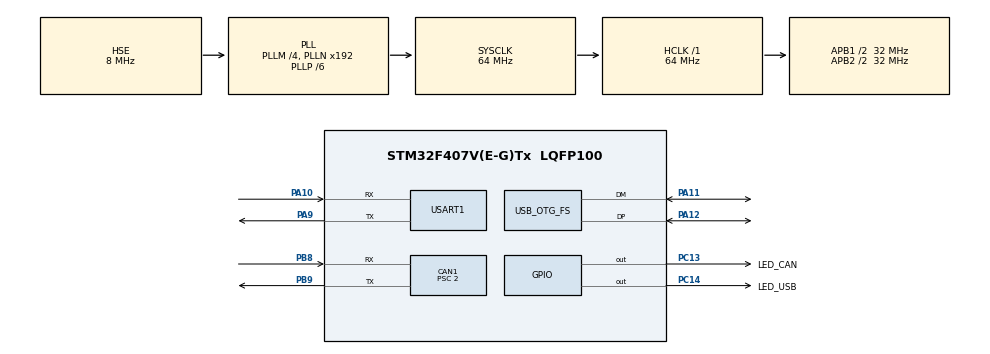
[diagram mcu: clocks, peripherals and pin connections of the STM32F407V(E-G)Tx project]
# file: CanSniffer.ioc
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CAN1.ABOM=ENABLE
CAN1.BS1=CAN_BS1_13TQ
CAN1.BS2=CAN_BS2_2TQ
CAN1.CalculateBaudRate=1000000
CAN1.CalculateTimeBit=1000
CAN1.CalculateTimeQuantum=62.5
CAN1.NART=ENABLE
CAN1.Prescaler=2
CAN1.RFLM=ENABLE
CAN1.TXFP=ENABLE
Mcu.Family=STM32F4
Mcu.Name=STM32F407V(E-G)Tx
Mcu.Package=LQFP100
NVIC.CAN1_RX0_IRQn=true\:0\:0\:true\:false\:true\:true\:true\:true
NVIC.CAN1_RX1_IRQn=true\:1\:0\:true\:false\:true\:true\:true\:true
NVIC.CAN1_SCE_IRQn=true\:1\:0\:true\:false\:true\:true\:true\:true
NVIC.CAN1_TX_IRQn=true\:1\:0\:true\:false\:true\:true\:true\:true
NVIC.OTG_FS_IRQn=true\:0\:0\:false\:false\:true\:false\:true\:true
NVIC.PriorityGroup=NVIC_PRIORITYGROUP_4
NVIC.TIM8_TRG_COM_TIM14_IRQn=true\:1\:0\:true\:false\:true\:true\:true\:true
NVIC.USART1_IRQn=true\:1\:0\:true\:false\:true\:true\:true\:true
PA10.Mode=Asynchronous
PA10.Signal=USART1_RX
PA11.Mode=Device_Only
PA11.Signal=USB_OTG_FS_DM
PA12.Mode=Device_Only
PA12.Signal=USB_OTG_FS_DP
PA13.Mode=Serial_Wire
PA13.Signal=SYS_JTMS-SWDIO
PA14.Mode=Serial_Wire
PA14.Signal=SYS_JTCK-SWCLK
PA9.Mode=Asynchronous
PA9.Signal=USART1_TX
PB8.GPIO_PuPd=GPIO_PULLUP
PB8.Mode=CAN_Activate
PB8.Signal=CAN1_RX
PB9.GPIO_PuPd=GPIO_PULLUP
PB9.Mode=CAN_Activate
PB9.Signal=CAN1_TX
PC13-ANTI_TAMP.GPIO_Label=LED_CAN
PC13-ANTI_TAMP.Signal=GPIO_Output
PC14-OSC32_IN.GPIO_Label=LED_USB
PC14-OSC32_IN.Signal=GPIO_Output
PH0-OSC_IN.Mode=HSE-External-Oscillator
PH0-OSC_IN.Signal=RCC_OSC_IN
PH1-OSC_OUT.Mode=HSE-External-Oscillator
PH1-OSC_OUT.Signal=RCC_OSC_OUT
ProjectManager.HeapSize=0x200
ProjectManager.StackSize=0x400
ProjectManager.TargetToolchain=STM32CubeIDE
RCC.48MHZClocksFreq_Value=48000000
RCC.AHBFreq_Value=64000000
RCC.APB1CLKDivider=RCC_HCLK_DIV2
RCC.APB1Freq_Value=32000000
RCC.APB1TimFreq_Value=64000000
RCC.APB2CLKDivider=RCC_HCLK_DIV2
RCC.APB2Freq_Value=32000000
RCC.APB2TimFreq_Value=64000000
RCC.CortexFreq_Value=64000000
RCC.HCLKFreq_Value=64000000
RCC.HSE_VALUE=8000000
RCC.HSI_VALUE=16000000
RCC.LSE_VALUE=32768
RCC.PLLM=4
RCC.PLLP=RCC_PLLP_DIV6
RCC.PLLQ=8
RCC.SYSCLKFreq_VALUE=64000000
RCC.SYSCLKSource=RCC_SYSCLKSOURCE_PLLCLK
RCC.VCOOutputFreq_Value=384000000
TIM14.Period=1000
TIM14.Prescaler=6399
USART1.VirtualMode=VM_ASYNC
USB_DEVICE.CLASS_NAME_FS=CDC
USB_DEVICE.MANUFACTURER_STRING-CDC_FS=Peleng
USB_DEVICE.PRODUCT_STRING_CDC_FS=CAN sniffer
USB_DEVICE.VirtualMode-CDC_FS=Cdc
USB_DEVICE.VirtualModeFS=Cdc_FS
USB_OTG_FS.VirtualMode=Device_Only
VP_TIM14_VS_ClockSourceINT.Mode=Enable_Timer
VP_USB_DEVICE_VS_USB_DEVICE_CDC_FS.Mode=CDC_FS
board=custom

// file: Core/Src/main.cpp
/* USER CODE BEGIN Header */
/**
  ******************************************************************************
  * @file           : main.c
  * @brief          : Main program body
  ******************************************************************************
  * @attention
  *
  * Copyright (c) 2025 STMicroelectronics.
  * All rights reserved.
  *
  * This software is licensed under terms that can be found in the LICENSE file
  * in the root directory of this software component.
  * If no LICENSE file comes with this software, it is provided AS-IS.
  *
  ******************************************************************************
  */
/* USER CODE END Header */

#include "main.h"
#include "can.h"
#include "usart.h"
#include "usb_device.h"
#include "gpio.h"
#include "tim.h"

/* USER CODE BEGIN Includes */
#include "App.hpp"
/* USER CODE END Includes */

void SystemClock_Config(void);

int main(void)
{

  /* MCU Configuration--------------------------------------------------------*/

  /* Reset of all peripherals, Initializes the Flash interface and the Systick. */
  HAL_Init();

  /* Configure the system clock */
  SystemClock_Config();

  /* Initialize all configured peripherals */
  MX_GPIO_Init();
  MX_CAN1_Init();
  MX_USB_DEVICE_Init();
  MX_USART1_UART_Init();
  MX_TIM14_Init();
  /* USER CODE BEGIN 2 */
  appInit();
  /* USER CODE END 2 */

  /* Infinite loop */
  while (1)
  {

    /* USER CODE BEGIN 3 */
	  appLoop();
  }
  /* USER CODE END 3 */
}

void SystemClock_Config(void)
{
  RCC_OscInitTypeDef RCC_OscInitStruct = {0};
  RCC_ClkInitTypeDef RCC_ClkInitStruct = {0};

  /** Configure the main internal regulator output voltage
  */
  __HAL_RCC_PWR_CLK_ENABLE();
  __HAL_PWR_VOLTAGESCALING_CONFIG(PWR_REGULATOR_VOLTAGE_SCALE1);

  /** Initializes the RCC Oscillators according to the specified parameters
  * in the RCC_OscInitTypeDef structure.
  */
  RCC_OscInitStruct.OscillatorType = RCC_OSCILLATORTYPE_HSE;
  RCC_OscInitStruct.HSEState = RCC_HSE_ON;
  RCC_OscInitStruct.PLL.PLLState = RCC_PLL_ON;
  RCC_OscInitStruct.PLL.PLLSource = RCC_PLLSOURCE_HSE;
  RCC_OscInitStruct.PLL.PLLM = 4;
  RCC_OscInitStruct.PLL.PLLN = 192;
  RCC_OscInitStruct.PLL.PLLP = RCC_PLLP_DIV6;
  RCC_OscInitStruct.PLL.PLLQ = 8;
  if (HAL_RCC_OscConfig(&RCC_OscInitStruct) != HAL_OK)
  {
    Error_Handler();
  }

  /** Initializes the CPU, AHB and APB buses clocks
  */
  RCC_ClkInitStruct.ClockType = RCC_CLOCKTYPE_HCLK|RCC_CLOCKTYPE_SYSCLK
                              |RCC_CLOCKTYPE_PCLK1|RCC_CLOCKTYPE_PCLK2;
  RCC_ClkInitStruct.SYSCLKSource = RCC_SYSCLKSOURCE_PLLCLK;
  RCC_ClkInitStruct.AHBCLKDivider = RCC_SYSCLK_DIV1;
  RCC_ClkInitStruct.APB1CLKDivider = RCC_HCLK_DIV2;
  RCC_ClkInitStruct.APB2CLKDivider = RCC_HCLK_DIV2;

  if (HAL_RCC_ClockConfig(&RCC_ClkInitStruct, FLASH_LATENCY_2) != HAL_OK)
  {
    Error_Handler();
  }
}

void Error_Handler(void)
{
  __disable_irq();
  while (1)
  {
  }
}
